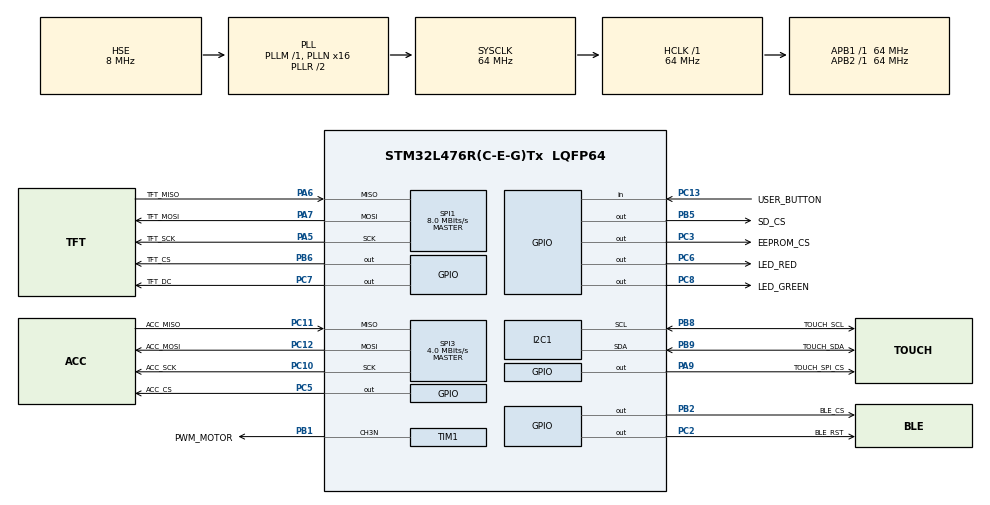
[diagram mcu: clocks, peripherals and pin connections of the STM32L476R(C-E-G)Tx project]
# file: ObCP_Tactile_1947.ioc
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Dma.Request0=SPI1_TX
Dma.Request1=TIM1_UP
Dma.SPI1_TX.0.Direction=DMA_MEMORY_TO_PERIPH
Dma.SPI1_TX.0.Instance=DMA1_Channel3
Dma.SPI1_TX.0.MemDataAlignment=DMA_MDATAALIGN_BYTE
Dma.SPI1_TX.0.MemInc=DMA_MINC_ENABLE
Dma.SPI1_TX.0.Mode=DMA_NORMAL
Dma.SPI1_TX.0.PeriphDataAlignment=DMA_PDATAALIGN_BYTE
Dma.SPI1_TX.0.PeriphInc=DMA_PINC_DISABLE
Dma.SPI1_TX.0.Priority=DMA_PRIORITY_MEDIUM
Dma.TIM1_UP.1.Direction=DMA_MEMORY_TO_PERIPH
Dma.TIM1_UP.1.Instance=DMA1_Channel6
Dma.TIM1_UP.1.MemDataAlignment=DMA_MDATAALIGN_HALFWORD
Dma.TIM1_UP.1.MemInc=DMA_MINC_ENABLE
Dma.TIM1_UP.1.Mode=DMA_CIRCULAR
Dma.TIM1_UP.1.PeriphDataAlignment=DMA_PDATAALIGN_HALFWORD
Dma.TIM1_UP.1.PeriphInc=DMA_PINC_DISABLE
Dma.TIM1_UP.1.Priority=DMA_PRIORITY_VERY_HIGH
I2C1.Timing=0x30A24457
Mcu.Family=STM32L4
Mcu.Name=STM32L476R(C-E-G)Tx
Mcu.Package=LQFP64
NVIC.DMA1_Channel3_IRQn=true\:2\:0\:false\:false\:true\:false\:true\:true
NVIC.DMA1_Channel6_IRQn=true\:1\:0\:false\:false\:true\:false\:true\:true
NVIC.PriorityGroup=NVIC_PRIORITYGROUP_4
NVIC.SPI1_IRQn=true\:3\:0\:false\:false\:true\:false\:true\:true
PA13\ (JTMS-SWDIO).GPIO_Label=TMS
PA13\ (JTMS-SWDIO).Mode=Serial_Wire
PA13\ (JTMS-SWDIO).Signal=SYS_JTMS-SWDIO
PA14\ (JTCK-SWCLK).GPIO_Label=TCK
PA14\ (JTCK-SWCLK).Mode=Serial_Wire
PA14\ (JTCK-SWCLK).Signal=SYS_JTCK-SWCLK
PA5.GPIO_Label=TFT_SCK
PA5.Mode=Full_Duplex_Master
PA5.Signal=SPI1_SCK
PA6.GPIO_Label=TFT_MISO
PA6.Mode=Full_Duplex_Master
PA6.Signal=SPI1_MISO
PA7.GPIO_Label=TFT_MOSI
PA7.Mode=Full_Duplex_Master
PA7.Signal=SPI1_MOSI
PA9.GPIO_Label=TOUCH_SPI_CS
PA9.PinState=GPIO_PIN_SET
PA9.Signal=GPIO_Output
PB1.GPIO_Label=PWM_MOTOR
PB1.Mode=PWM Generation3 CH3N
PB1.Signal=TIM1_CH3N
PB2.GPIO_Label=BLE_CS
PB2.PinState=GPIO_PIN_SET
PB2.Signal=GPIO_Output
PB5.GPIO_Label=SD_CS
PB5.PinState=GPIO_PIN_SET
PB5.Signal=GPIO_Output
PB6.GPIO_Label=TFT_CS
PB6.PinState=GPIO_PIN_SET
PB6.Signal=GPIO_Output
PB8.GPIO_Label=TOUCH_SCL
PB8.Mode=I2C
PB8.Signal=I2C1_SCL
PB9.GPIO_Label=TOUCH_SDA
PB9.Mode=I2C
PB9.Signal=I2C1_SDA
PC10.GPIO_Label=ACC_SCK
PC10.Mode=Full_Duplex_Master
PC10.Signal=SPI3_SCK
PC11.GPIO_Label=ACC_MISO
PC11.Mode=Full_Duplex_Master
PC11.Signal=SPI3_MISO
PC12.GPIO_Label=ACC_MOSI
PC12.Mode=Full_Duplex_Master
PC12.Signal=SPI3_MOSI
PC13.GPIO_Label=USER_BUTTON
PC13.Signal=GPIO_Input
PC2.GPIO_Label=BLE_RST
PC2.Signal=GPIO_Output
PC3.GPIO_Label=EEPROM_CS
PC3.PinState=GPIO_PIN_SET
PC3.Signal=GPIO_Output
PC5.GPIO_Label=ACC_CS
PC5.PinState=GPIO_PIN_SET
PC5.Signal=GPIO_Output
PC6.GPIO_Label=LED_RED
PC6.Signal=GPIO_Output
PC7.GPIO_Label=TFT_DC
PC7.PinState=GPIO_PIN_SET
PC7.Signal=GPIO_Output
PC8.GPIO_Label=LED_GREEN
PC8.Signal=GPIO_Output
PH0-OSC_IN\ (PH0).Mode=HSE-External-Oscillator
PH0-OSC_IN\ (PH0).Signal=RCC_OSC_IN
PH1-OSC_OUT\ (PH1).Mode=HSE-External-Oscillator
PH1-OSC_OUT\ (PH1).Signal=RCC_OSC_OUT
ProjectManager.HeapSize=0x400
ProjectManager.StackSize=0x1000
ProjectManager.TargetToolchain=STM32CubeIDE
RCC.ADCFreq_Value=48000000
RCC.AHBFreq_Value=64000000
RCC.APB1Freq_Value=64000000
RCC.APB1TimFreq_Value=64000000
RCC.APB2Freq_Value=64000000
RCC.APB2TimFreq_Value=64000000
RCC.CortexFreq_Value=64000000
RCC.HCLKFreq_Value=64000000
RCC.HSE_VALUE=8000000
RCC.HSI_VALUE=16000000
RCC.LSE_VALUE=32768
RCC.MSI_VALUE=4000000
RCC.PLLN=16
RCC.PLLSAI1N=12
RCC.PLLSourceVirtual=RCC_PLLSOURCE_HSE
RCC.PREFETCH_ENABLE=1
RCC.SYSCLKFreq_VALUE=64000000
RCC.SYSCLKSource=RCC_SYSCLKSOURCE_PLLCLK
RCC.USBFreq_Value=48000000
RCC.VCOOutputFreq_Value=128000000
SPI1.BaudRatePrescaler=SPI_BAUDRATEPRESCALER_8
SPI1.CalculateBaudRate=8.0 MBits/s
SPI1.DataSize=SPI_DATASIZE_8BIT
SPI1.Direction=SPI_DIRECTION_2LINES
SPI1.Mode=SPI_MODE_MASTER
SPI1.NSSPMode=SPI_NSS_PULSE_DISABLE
SPI1.VirtualType=VM_MASTER
SPI3.BaudRatePrescaler=SPI_BAUDRATEPRESCALER_16
SPI3.CLKPolarity=SPI_POLARITY_LOW
SPI3.CalculateBaudRate=4.0 MBits/s
SPI3.DataSize=SPI_DATASIZE_8BIT
SPI3.Direction=SPI_DIRECTION_2LINES
SPI3.Mode=SPI_MODE_MASTER
SPI3.NSSPMode=SPI_NSS_PULSE_DISABLE
SPI3.VirtualType=VM_MASTER
TIM1.AutoReloadPreload=TIM_AUTORELOAD_PRELOAD_ENABLE
TIM1.Channel-PWM\ Generation3\ CH3N=TIM_CHANNEL_3
TIM1.OC3Preload_PWM=ENABLE
TIM1.OffStateIDLEMode=TIM_OSSI_ENABLE
TIM1.Period=1023
TIM1.Prescaler=0
TIM1.RepetitionCounter=3
VP_TIM1_VS_ClockSourceINT.Mode=Internal
board=NUCLEO-L476RG

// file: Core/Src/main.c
/* USER CODE BEGIN Header */
/**
  ******************************************************************************
  * @file           : main.c
  * @brief          : Main program body
  ******************************************************************************
  * @attention
  *
  * Copyright (c) 2026 STMicroelectronics.
  * All rights reserved.
  *
  * This software is licensed under terms that can be found in the LICENSE file
  * in the root directory of this software component.
  * If no LICENSE file comes with this software, it is provided AS-IS.
  *
  ******************************************************************************
  */
/* USER CODE END Header */
#include "main.h"
#include "dma.h"
#include "i2c.h"
#include "spi.h"
#include "tim.h"
#include "gpio.h"

/* USER CODE BEGIN Includes */
/* La seule interface de la carte vers l’application est obcp_board.h. Les modèles et pilotes restent dans Core/Src/obcp. */
#include "obcp_board.h"

/* USER CODE END Includes */

void SystemClock_Config(void);

int main(void)
{

  /* USER CODE BEGIN 1 */
  /* Point d’entrée après Reset_Handler. Celui-ci a initialisé .data, .bss et la pile avant de nous appeler. Les accès HAL attendent HAL_Init. */

  /* USER CODE END 1 */

  /* MCU Configuration--------------------------------------------------------*/

  /* Reset of all peripherals, Initializes the Flash interface and the Systick. */
  HAL_Init();

  /* USER CODE BEGIN Init */
  /* HAL_Init installe le tick milliseconde. Les délais et les échéances applicatives utiliseront HAL_GetTick. */

  /* USER CODE END Init */

  /* Configure the system clock */
  SystemClock_Config();

  /* USER CODE BEGIN SysInit */
  /* HSE 8 MHz, PLL ×16 puis division par 2 donnent 64 MHz. AHB et APB restent à 64 MHz. Voir SystemClock_Config et le .ioc. */

  /* USER CODE END SysInit */

  /* Initialize all configured peripherals */
  MX_GPIO_Init();
  MX_DMA_Init();
  MX_SPI1_Init();
  MX_SPI3_Init();
  MX_I2C1_Init();
  MX_TIM1_Init();
  /* USER CODE BEGIN 2 */
  /* Les GPIO, DMA, SPI, I²C et TIM1 sont prêts. Initialiser une seule fois les modèles, les sauvegardes et les composants externes. */
  obcp_start();

  /* USER CODE END 2 */

  /* Infinite loop */
  /* USER CODE BEGIN WHILE */
  /* Boucle coopérative sans RTOS. Chaque tour doit rendre la main rapidement pour partager le processeur entre audio, entrées et affichage. */
  while (1)
  {
    /* USER CODE END WHILE */

    /* USER CODE BEGIN 3 */
    /* Une itération sert les tâches et les échéances. Ne pas ajouter ici de longue attente HAL_Delay, qui retarderait audio et tactile. */
    obcp_task();
  }
  /* USER CODE END 3 */
}

void SystemClock_Config(void)
{
  RCC_OscInitTypeDef RCC_OscInitStruct = {0};
  RCC_ClkInitTypeDef RCC_ClkInitStruct = {0};

  /** Configure the main internal regulator output voltage
  */
  if (HAL_PWREx_ControlVoltageScaling(PWR_REGULATOR_VOLTAGE_SCALE1) != HAL_OK)
  {
    Error_Handler();
  }

  /** Initializes the RCC Oscillators according to the specified parameters
  * in the RCC_OscInitTypeDef structure.
  */
  RCC_OscInitStruct.OscillatorType = RCC_OSCILLATORTYPE_HSE;
  RCC_OscInitStruct.HSEState = RCC_HSE_ON;
  RCC_OscInitStruct.PLL.PLLState = RCC_PLL_ON;
  RCC_OscInitStruct.PLL.PLLSource = RCC_PLLSOURCE_HSE;
  RCC_OscInitStruct.PLL.PLLM = 1;
  RCC_OscInitStruct.PLL.PLLN = 16;
  RCC_OscInitStruct.PLL.PLLP = RCC_PLLP_DIV7;
  RCC_OscInitStruct.PLL.PLLQ = RCC_PLLQ_DIV2;
  RCC_OscInitStruct.PLL.PLLR = RCC_PLLR_DIV2;
  if (HAL_RCC_OscConfig(&RCC_OscInitStruct) != HAL_OK)
  {
    Error_Handler();
  }

  /** Initializes the CPU, AHB and APB buses clocks
  */
  RCC_ClkInitStruct.ClockType = RCC_CLOCKTYPE_HCLK|RCC_CLOCKTYPE_SYSCLK
                              |RCC_CLOCKTYPE_PCLK1|RCC_CLOCKTYPE_PCLK2;
  RCC_ClkInitStruct.SYSCLKSource = RCC_SYSCLKSOURCE_PLLCLK;
  RCC_ClkInitStruct.AHBCLKDivider = RCC_SYSCLK_DIV1;
  RCC_ClkInitStruct.APB1CLKDivider = RCC_HCLK_DIV1;
  RCC_ClkInitStruct.APB2CLKDivider = RCC_HCLK_DIV1;

  if (HAL_RCC_ClockConfig(&RCC_ClkInitStruct, FLASH_LATENCY_3) != HAL_OK)
  {
    Error_Handler();
  }
}

void Error_Handler(void)
{
  /* USER CODE BEGIN Error_Handler_Debug */
  /* Échec d’initialisation HAL. Le processeur s’arrête avec les interruptions coupées. En Debug, placer un point d’arrêt ici et remonter la pile d’appels. */
  /* User can add his own implementation to report the HAL error return state */
  __disable_irq();
  while (1)
  {
  }
  /* USER CODE END Error_Handler_Debug */
}

#ifdef  USE_FULL_ASSERT
/**
  * @brief  Reports the name of the source file and the source line number
  *         where the assert_param error has occurred.
  * @param  file: pointer to the source file name
  * @param  line: assert_param error line source number
  * @retval None
  */
void assert_failed(uint8_t *file, uint32_t line)
{
  /* USER CODE BEGIN 6 */
  /* Crochet des assertions HAL si USE_FULL_ASSERT est activé. file et line identifient le paramètre refusé. Aucun printf n’est configuré par défaut. */
  /* User can add his own implementation to report the file name and line number,
     ex: printf("Wrong parameters value: file %s on line %d\r\n", file, line) */
  /* USER CODE END 6 */
}
#endif /* USE_FULL_ASSERT */
